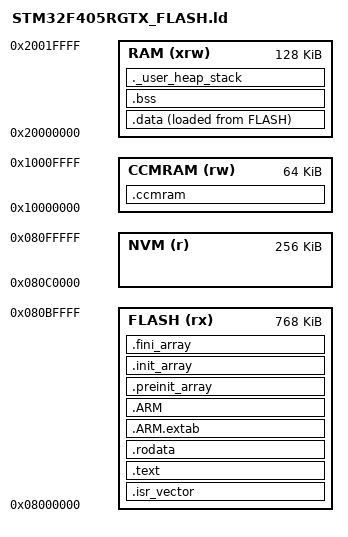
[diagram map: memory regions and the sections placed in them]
/**
 ******************************************************************************
 * @file      LinkerScript.ld
 * @author    Auto-generated by STM32CubeIDE
 * @brief     Linker script for STM32F405RGTx Device from STM32F4 series
 *                      1024Kbytes FLASH
 *                      64Kbytes CCMRAM
 *                      128Kbytes RAM
 *
 *            Set heap size, stack size and stack location according
 *            to application requirements.
 *
 *            Set memory bank area and size if external memory is used
 ******************************************************************************
 * @attention
 *
 * <h2><center>&copy; Copyright (c) 2020 STMicroelectronics.
 * All rights reserved.</center></h2>
 *
 * This software component is licensed by ST under BSD 3-Clause license,
 * the "License"; You may not use this file except in compliance with the
 * License. You may obtain a copy of the License at:
 *                        opensource.org/licenses/BSD-3-Clause
 *
 ******************************************************************************
 * startup file : C:\Users\jinsheng\.platformio\packages\framework-stm32cubef4\Drivers\CMSIS\Device\ST\STM32F4xx\Source\Templates\gcc\startup_stm32f405xx.s
 */

/* Entry Point */
ENTRY(Reset_Handler)

/* Highest address of the user mode stack */
_estack = ORIGIN(RAM) + LENGTH(RAM);	/* end of "RAM" Ram type memory */

/* 更新 栈stack和堆heap的大小 */
/* 嵌入式系统不建议动态申请内存，所以堆空间尽量不要用 */
/* 项目角度，尽量用局部变量，因此stack要多用 */
/* 对于GCC来说，会把栈顶地址放在RAM的最高地址，因此这里设置只是用于验证stack和heap是否够用，而不是真正的stack和heap size */
/* 因此对于GCC来说，这里的值的唯一意义就是结合.map文件，查看 全局变量+_Min_Heap_Size+_Min_Stack_Size 是否大于等于ram size[是否溢出]*/
_Min_Heap_Size = 0x1000;	/* 4k, required amount of heap 默认0x200, 512Byte  */ 
_Min_Stack_Size = 0x6400;	/* 25k, required amount of stack 默认0x400, 1kByte*/

/* Memories definition */
MEMORY
{
  CCMRAM    (rw)    : ORIGIN = 0x10000000,   LENGTH = 64K /* 查看数据是否在ccram，查看.map文件 */
  RAM    (xrw)    : ORIGIN = 0x20000000,   LENGTH = 128K /* ram最大地址：0x2002 0000 [128k] */
  FLASH (rx)      : ORIGIN = 0x8000000, LENGTH = 768K
  NVM (r)         : ORIGIN = 0x80C0000, LENGTH = 256K
}

/* Sections */
SECTIONS
{
  /* The startup code into "FLASH" Rom type memory */
  .isr_vector :
  {
    . = ALIGN(4);
    KEEP(*(.isr_vector)) /* Startup code */
    . = ALIGN(4);
  } >FLASH

  /* The program code and other data into "FLASH" Rom type memory */
  .text :
  {
    . = ALIGN(4);
    *(.text)           /* .text sections (code) */
    *(.text*)          /* .text* sections (code) */
    *(.glue_7)         /* glue arm to thumb code */
    *(.glue_7t)        /* glue thumb to arm code */
    *(.eh_frame)

    /* section information for shell */
    . = ALIGN(4);
    __shell_section_start = .;
    KEEP(*(SHELL_SECTION))
    __shell_section_end = .;

    KEEP (*(.init))
    KEEP (*(.fini))

    . = ALIGN(4);
    _etext = .;        /* define a global symbols at end of code */
  } >FLASH

  /* Constant data into "FLASH" Rom type memory */
  .rodata :
  {
    . = ALIGN(4);
    *(.rodata)         /* .rodata sections (constants, strings, etc.) */
    *(.rodata*)        /* .rodata* sections (constants, strings, etc.) */
    . = ALIGN(4);
  } >FLASH

  .ARM.extab   : { 
    . = ALIGN(4);
    *(.ARM.extab* .gnu.linkonce.armextab.*)
    . = ALIGN(4);
  } >FLASH
  
  .ARM : {
    . = ALIGN(4);
    __exidx_start = .;
    *(.ARM.exidx*)
    __exidx_end = .;
    . = ALIGN(4);
  } >FLASH

  .preinit_array     :
  {
    . = ALIGN(4);
    PROVIDE_HIDDEN (__preinit_array_start = .);
    KEEP (*(.preinit_array*))
    PROVIDE_HIDDEN (__preinit_array_end = .);
    . = ALIGN(4);
  } >FLASH
  
  .init_array :
  {
    . = ALIGN(4);
    PROVIDE_HIDDEN (__init_array_start = .);
    KEEP (*(SORT(.init_array.*)))
    KEEP (*(.init_array*))
    PROVIDE_HIDDEN (__init_array_end = .);
    . = ALIGN(4);
  } >FLASH
  
  .fini_array :
  {
    . = ALIGN(4);
    PROVIDE_HIDDEN (__fini_array_start = .);
    KEEP (*(SORT(.fini_array.*)))
    KEEP (*(.fini_array*))
    PROVIDE_HIDDEN (__fini_array_end = .);
    . = ALIGN(4);
  } >FLASH

  /* Used by the startup to initialize data */
  _sidata = LOADADDR(.data);

  /* Initialized data sections into "RAM" Ram type memory */
  .data : 
  {
    . = ALIGN(4);
    _sdata = .;        /* create a global symbol at data start */
    *(.data)           /* .data sections */
    *(.data*)          /* .data* sections */

    . = ALIGN(4);
    _edata = .;        /* define a global symbol at data end */
    
  } >RAM AT> FLASH

  _siccmram = LOADADDR(.ccmram);

  /* CCM-RAM section 
  * 
  * IMPORTANT NOTE! 
  * If initialized variables will be placed in this section,
  * the startup code needs to be modified to copy the init-values.
  * Oskar: Added NOLOAD to remove this section from .bin outputs
  */
  .ccmram (NOLOAD) :
  {
    . = ALIGN(4);
    _sccmram = .;       /* create a global symbol at ccmram start */
    *(.ccmram)
    *(.ccmram*)
    
    . = ALIGN(4);
    _eccmram = .;       /* create a global symbol at ccmram end */
  } >CCMRAM /*AT> FLASH*/

  /* Uninitialized data section into "RAM" Ram type memory */
  . = ALIGN(4);
  .bss :
  {
    /* This is used by the startup in order to initialize the .bss section */
    _sbss = .;         /* define a global symbol at bss start */
    __bss_start__ = _sbss;
    *(.bss)
    *(.bss*)
    *(COMMON)

    . = ALIGN(4);
    _ebss = .;         /* define a global symbol at bss end */
    __bss_end__ = _ebss;
  } >RAM

  /* User_heap_stack section, used to check that there is enough "RAM" Ram  type memory left */
  ._user_heap_stack :
  {
    . = ALIGN(8);
    PROVIDE ( end = . );
    PROVIDE ( _end = . );
    . = . + _Min_Heap_Size;
    . = . + _Min_Stack_Size;
    . = ALIGN(8);
  } >RAM

  /* Remove information from the compiler libraries */
  /DISCARD/ :
  {
    libc.a ( * )
    libm.a ( * )
    libgcc.a ( * )
  }

  .ARM.attributes 0 : { *(.ARM.attributes) }
}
